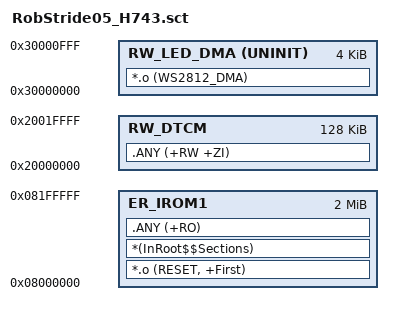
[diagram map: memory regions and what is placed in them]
; Internal Flash + DTCM; only WS2812_DMA uses internal D2 SRAM1.
; Caches stay OFF (no I-Cache/D-Cache setup and no cache maintenance), so the
; interrupt/DMA driver memories need no cache maintenance either.
LR_IROM1 0x08000000 0x00200000 {
 ER_IROM1 0x08000000 0x00200000 {
  *.o (RESET, +First)
  *(InRoot$$Sections)
  .ANY (+RO)
 }
 ; No CRT zeroing before the BSP enables the SRAM1 clock.
 RW_LED_DMA 0x30000000 UNINIT 0x00001000 {
  *.o (WS2812_DMA)
 }
 ; FreeRTOS heap, task stacks, g_debug and all application state live here.
 RW_DTCM 0x20000000 0x00020000 {
  .ANY (+RW +ZI)
 }
}
